VERSION ""

NS_ :

BS_:

BU_: FAKE_ECU

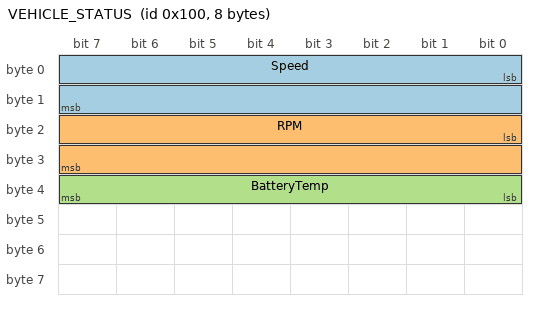
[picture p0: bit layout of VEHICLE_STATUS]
BO_ 256 VEHICLE_STATUS: 8 FAKE_ECU
 SG_ Speed : 0|16@1+ (0.01,0) [0|655.35] "km/h" Vector__XXX
 SG_ RPM : 16|16@1+ (0.25,0) [0|16383.75] "rpm" Vector__XXX
 SG_ BatteryTemp : 32|8@1+ (1,-40) [-40|215] "degC" Vector__XXX

CM_ BO_ 256 "Fake vehicle status message for CAN-Net Stage 2 Task 7";
CM_ SG_ 256 Speed "Vehicle speed";
CM_ SG_ 256 RPM "Engine RPM";
CM_ SG_ 256 BatteryTemp "Battery temperature";
